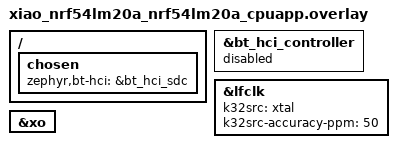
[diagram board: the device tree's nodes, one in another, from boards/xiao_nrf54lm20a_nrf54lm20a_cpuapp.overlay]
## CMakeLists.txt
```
cmake_minimum_required(VERSION 3.20.0)

find_package(Zephyr REQUIRED HINTS $ENV{ZEPHYR_BASE})
project(003_ble_scan)

zephyr_library_sources(src/main.c)
```

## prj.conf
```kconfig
CONFIG_LOG=y
CONFIG_BT=y
CONFIG_BT_OBSERVER=y
```

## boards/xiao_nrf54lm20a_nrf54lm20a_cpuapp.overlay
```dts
/* Use the SoftDevice Controller instead of Zephyr link layer. */
/ {
	chosen {
		zephyr,bt-hci = &bt_hci_sdc;
	};
};

/* Turn the Zephyr link layer off. */
&bt_hci_controller {
	status = "disabled";
};

/* Use the onboard crystal for the 32 kHz clock source. */
&lfclk {
	status = "okay";
	k32src = "xtal";
	k32src-accuracy-ppm = <50>;
};

/* Enable the 32 MHz high-frequency oscillator. */
&xo {
	status = "okay";
};
```

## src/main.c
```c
#include <zephyr/bluetooth/bluetooth.h>
#include <zephyr/kernel.h>
#include <zephyr/logging/log.h>

LOG_MODULE_REGISTER(ble_scan, LOG_LEVEL_INF);

static void
callback(const bt_addr_le_t *addr, int8_t rssi, uint8_t type, struct net_buf_simple *ad) {
    LOG_INF("%s rssi=%d type=%u len=%u", bt_addr_le_str(addr), rssi, type, ad->len);
    LOG_HEXDUMP_INF(ad->data, ad->len, "ad");
}

int main(void) {
    int rc;

    LOG_INF("board=%s soc=%s", CONFIG_BOARD, CONFIG_SOC);

    rc = bt_enable(NULL);
    if (rc < 0) {
        LOG_ERR("Bluetooth init failed: %d", rc);
        return rc;
    }

    rc = bt_le_scan_start(BT_LE_SCAN_CODED_PASSIVE, callback);
    if (rc < 0) {
        LOG_ERR("Bluetooth LE scan start failed: %d", rc);
        return rc;
    }

    LOG_INF("Bluetooth LE scan started...");
    return 0;
}
```
